VERSION ""

NS_ :

BS_:
BU_: ECU
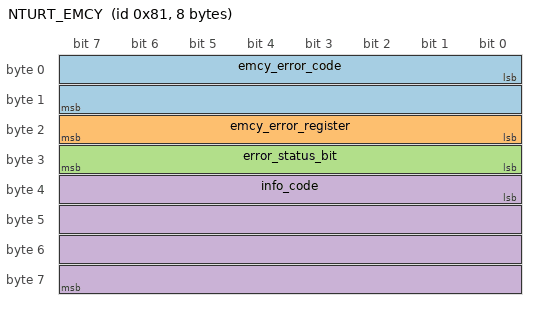
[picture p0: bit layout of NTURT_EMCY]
BO_ 129 NTURT_EMCY: 8 ECU
   SG_ emcy_error_code : 0|16@1+ (1,0) [0|65535] "" ECU
   SG_ emcy_error_register : 16|8@1+ (1,0) [0|255] "" ECU
   SG_ error_status_bit : 24|8@1+ (1,0) [0|255] "" ECU
   SG_ info_code : 32|32@1+ (1,0) [0|4.29497e+09] "" ECU

CM_ SG_ 129 emcy_error_code "0x0000=No_Error,_other=Error_Code";
BA_DEF_ BO_ "GenMsgBackgroundColor" STRING ;
BA_DEF_ BO_ "GenMsgForegroundColor" STRING ;
BA_DEF_ BO_ "labelfilters" INT 0 0;
BA_DEF_ BO_ "filterlabeling" INT 0 0;
BA_DEF_DEF_ "GenMsgBackgroundColor" "#ffffff";
BA_DEF_DEF_ "GenMsgForegroundColor" "#000000";
BA_DEF_DEF_ "labelfilters" 1;
BA_DEF_DEF_ "filterlabeling" 1;
BA_ "GenMsgBackgroundColor" BO_ 129 "#ff0000";
VAL_ 129 emcy_error_code 0 "ERROR_CLEARED" 65296 "ERROR_SET";
VAL_ 129 error_status_bit 0 "No Description";
VAL_ 129 info_code 0 "ERROR_STEER" 1 "ERROR_ACCEL" 2 "ERROR_APPS1" 3 "ERROR_APPS2" 4 "ERROR_BRAKE" 5 "ERROR_BSE1" 6 "ERROR_BSE2" 7 "ERROR_PEDAL_PLAUS" 8 "ERROR_ACC" 9 "ERROR_ACC_COMM" 10 "ERROR_INV_FL" 11 "ERROR_INV_FR" 12 "ERROR_INV_RL" 13 "ERROR_INV_RR" 14 "ERROR_INV_HVL_FL" 15 "ERROR_INV_HVL_FR" 16 "ERROR_INV_HVL_RL" 17 "ERROR_INV_HVL_RR" 18 "ERROR_EMCY_START";
